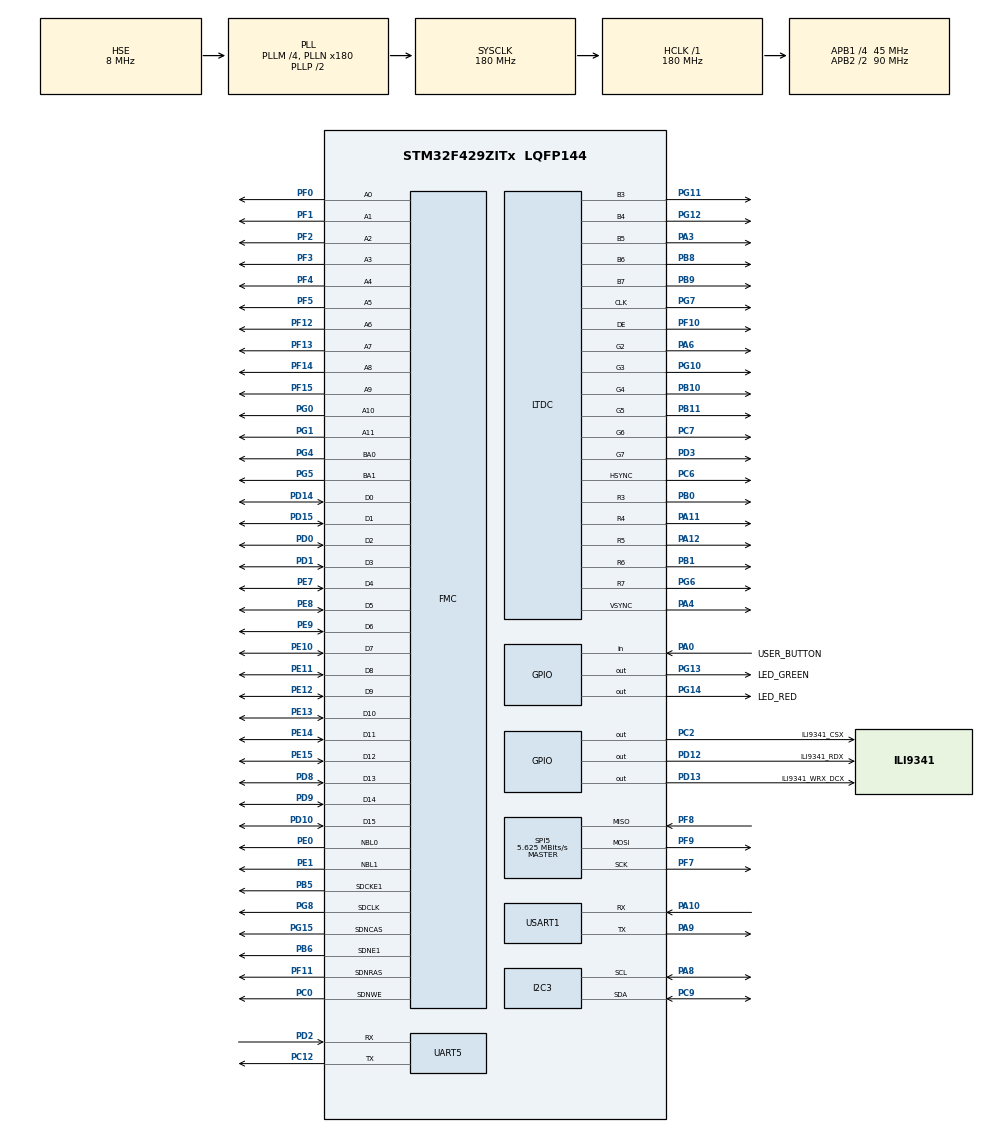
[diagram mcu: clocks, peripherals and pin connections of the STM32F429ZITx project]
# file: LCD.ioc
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DMA2D.ColorMode=DMA2D_OUTPUT_RGB565
FMC.CASLatency1=FMC_SDRAM_CAS_LATENCY_3
FMC.ExitSelfRefreshDelay1=7
FMC.LoadToActiveDelay1=2
FMC.RCDDelay1=2
FMC.RPDelay1=2
FMC.RPDelay2=2
FMC.RowCycleDelay1=7
FMC.RowCycleDelay2=7
FMC.SDClockPeriod1=FMC_SDRAM_CLOCK_PERIOD_2
FMC.SDClockPeriod2=FMC_SDRAM_CLOCK_PERIOD_2
FMC.SelfRefreshTime1=4
FMC.WriteRecoveryTime1=3
GRAPHICS.BSP.number=4
GRAPHICS.Check_OTM8009A_PixelFormat-STemWin_F429_439=1
GRAPHICS.DMA2D_Graphics-STemWin_F429_439=1
GRAPHICS.EA_1_Apptype=Window
GRAPHICS.EA_1_executable_name-STemWin_F429_439=GUIBuilder.exe
GRAPHICS.GUI_NUM_LAYERS-STemWin_F429_439=1
GRAPHICS.LIN_Frame_Buffer_Depth_Layer0-STemWin_F429_439=16
GRAPHICS.OPTIM_OS_use-STemWin_F429_439=4
GRAPHICS.USE_Embedded_Wizard-STemWin_F429_439=0
GRAPHICS.USE_STTouchGFX-STemWin_F429_439=0
GRAPHICS.UseGUIBuilder=Enabled
GRAPHICS.Use_SDRAM-STemWin_F429_439=SDRAM1_BANK2
GRAPHICS.Use_ili9341_Check-STemWin_F429_439=1
GRAPHICS0.BSP.STBoard=false
GRAPHICS0.BSP.api=Unknown
GRAPHICS0.BSP.i2caddr=0
GRAPHICS0.BSP.instance=PC2
GRAPHICS0.BSP.ip=GPIO
GRAPHICS0.BSP.mode=Output
GRAPHICS0.BSP.name=Chip Select
GRAPHICS0.BSP.solution=PC2
GRAPHICS1.BSP.STBoard=false
GRAPHICS1.BSP.api=Unknown
GRAPHICS1.BSP.i2caddr=0
GRAPHICS1.BSP.instance=PD13
GRAPHICS1.BSP.ip=GPIO
GRAPHICS1.BSP.mode=Output
GRAPHICS1.BSP.name=WRX High
GRAPHICS1.BSP.solution=PD13
GRAPHICS2.BSP.STBoard=false
GRAPHICS2.BSP.api=Unknown
GRAPHICS2.BSP.i2caddr=0
GRAPHICS2.BSP.instance=SPI5
GRAPHICS2.BSP.ip=SPI
GRAPHICS2.BSP.mode=Full-Duplex Master
GRAPHICS2.BSP.name=SPI_PIN
GRAPHICS2.BSP.solution=SPI5
GRAPHICS3.BSP.STBoard=false
GRAPHICS3.BSP.api=Unknown
GRAPHICS3.BSP.i2caddr=0
GRAPHICS3.BSP.instance=PD12
GRAPHICS3.BSP.ip=GPIO
GRAPHICS3.BSP.mode=Output
GRAPHICS3.BSP.name=RDX High
GRAPHICS3.BSP.solution=PD12
LTDC.ActiveH=320
LTDC.ActiveW=240
LTDC.Alpha_L0=255
LTDC.BlendingFactor1_L0=LTDC_BLENDING_FACTOR1_PAxCA
LTDC.BlendingFactor2_L0=LTDC_BLENDING_FACTOR2_PAxCA
LTDC.FBStartAdress_L0=0xd0200000
LTDC.HBP=20
LTDC.HFP=10
LTDC.HSync=10
LTDC.ImageHeight_L0=320
LTDC.ImageWidth_L0=240
LTDC.Layers=0
LTDC.PixelFormat_L0=LTDC_PIXEL_FORMAT_RGB565
LTDC.VFP=4
LTDC.VSync=2
LTDC.WindowX1_L0=240
LTDC.WindowY1_L0=320
Mcu.Family=STM32F4
Mcu.Name=STM32F429ZITx
Mcu.Package=LQFP144
NVIC.DMA2D_IRQn=true\:0\:0\:false\:false\:true\:true\:true
NVIC.LTDC_IRQn=true\:0\:0\:false\:false\:true\:true\:true
NVIC.PriorityGroup=NVIC_PRIORITYGROUP_4
NVIC.UART5_IRQn=true\:0\:0\:false\:false\:true\:true\:true
NVIC.USART1_IRQn=true\:0\:0\:false\:false\:true\:true\:true
PA0/WKUP.GPIO_Label=USER_BUTTON
PA0/WKUP.Signal=GPIO_Input
PA10.Mode=Asynchronous
PA10.Signal=USART1_RX
PA11.Mode=RGB565
PA11.Signal=LTDC_R4
PA12.Mode=RGB565
PA12.Signal=LTDC_R5
PA3.Mode=RGB565
PA3.Signal=LTDC_B5
PA4.Mode=RGB565
PA4.Signal=LTDC_VSYNC
PA6.Mode=RGB565
PA6.Signal=LTDC_G2
PA8.Mode=I2C
PA8.Signal=I2C3_SCL
PA9.Mode=Asynchronous
PA9.Signal=USART1_TX
PB0.Mode=RGB565
PB0.Signal=LTDC_R3
PB1.Mode=RGB565
PB1.Signal=LTDC_R6
PB10.Mode=RGB565
PB10.Signal=LTDC_G4
PB11.Mode=RGB565
PB11.Signal=LTDC_G5
PB5.Mode=SdramChipSelect2_1
PB5.Signal=FMC_SDCKE1
PB6.Mode=SdramChipSelect2_1
PB6.Signal=FMC_SDNE1
PB8.Mode=RGB565
PB8.Signal=LTDC_B6
PB9.Mode=RGB565
PB9.Signal=LTDC_B7
PC0.Signal=FMC_SDNWE
PC12.Mode=Asynchronous
PC12.Signal=UART5_TX
PC2.GPIO_Label=ILI9341_CSX
PC2.Signal=GPIO_Output
PC6.Mode=RGB565
PC6.Signal=LTDC_HSYNC
PC7.Mode=RGB565
PC7.Signal=LTDC_G6
PC9.Mode=I2C
PC9.Signal=I2C3_SDA
PD0.Signal=FMC_D2_DA2
PD1.Signal=FMC_D3_DA3
PD10.Signal=FMC_D15_DA15
PD12.GPIO_Label=ILI9341_RDX
PD12.Signal=GPIO_Output
PD13.GPIO_Label=ILI9341_WRX_DCX
PD13.Signal=GPIO_Output
PD14.Signal=FMC_D0_DA0
PD15.Signal=FMC_D1_DA1
PD2.Mode=Asynchronous
PD2.Signal=UART5_RX
PD3.Mode=RGB565
PD3.Signal=LTDC_G7
PD8.Signal=FMC_D13_DA13
PD9.Signal=FMC_D14_DA14
PE0.Signal=FMC_NBL0
PE1.Signal=FMC_NBL1
PE10.Signal=FMC_D7_DA7
PE11.Signal=FMC_D8_DA8
PE12.Signal=FMC_D9_DA9
PE13.Signal=FMC_D10_DA10
PE14.Signal=FMC_D11_DA11
PE15.Signal=FMC_D12_DA12
PE7.Signal=FMC_D4_DA4
PE8.Signal=FMC_D5_DA5
PE9.Signal=FMC_D6_DA6
PF0.Signal=FMC_A0
PF1.Signal=FMC_A1
PF10.Mode=RGB565
PF10.Signal=LTDC_DE
PF11.Signal=FMC_SDNRAS
PF12.Signal=FMC_A6
PF13.Signal=FMC_A7
PF14.Signal=FMC_A8
PF15.Signal=FMC_A9
PF2.Signal=FMC_A2
PF3.Signal=FMC_A3
PF4.Signal=FMC_A4
PF5.Signal=FMC_A5
PF7.Mode=Full_Duplex_Master
PF7.Signal=SPI5_SCK
PF8.Mode=Full_Duplex_Master
PF8.Signal=SPI5_MISO
PF9.Mode=Full_Duplex_Master
PF9.Signal=SPI5_MOSI
PG0.Signal=FMC_A10
PG1.Signal=FMC_A11
PG10.Mode=RGB565
PG10.Signal=LTDC_G3
PG11.Mode=RGB565
PG11.Signal=LTDC_B3
PG12.Mode=RGB565
PG12.Signal=LTDC_B4
PG13.GPIO_Label=LED_GREEN
PG13.Signal=GPIO_Output
PG14.GPIO_Label=LED_RED
PG14.Signal=GPIO_Output
PG15.Signal=FMC_SDNCAS
PG4.Signal=FMC_A14_BA0
PG5.Signal=FMC_A15_BA1
PG6.Mode=RGB565
PG6.Signal=LTDC_R7
PG7.Mode=RGB565
PG7.Signal=LTDC_CLK
PG8.Signal=FMC_SDCLK
PH0/OSC_IN.Mode=HSE-External-Oscillator
PH0/OSC_IN.Signal=RCC_OSC_IN
PH1/OSC_OUT.Mode=HSE-External-Oscillator
PH1/OSC_OUT.Signal=RCC_OSC_OUT
ProjectManager.HeapSize=0x1000
ProjectManager.StackSize=0x1000
ProjectManager.TargetToolchain=TrueSTUDIO
RCC.48MHZClocksFreq_Value=90000000
RCC.AHBFreq_Value=180000000
RCC.APB1CLKDivider=RCC_HCLK_DIV4
RCC.APB1Freq_Value=45000000
RCC.APB1TimFreq_Value=90000000
RCC.APB2CLKDivider=RCC_HCLK_DIV2
RCC.APB2Freq_Value=90000000
RCC.APB2TimFreq_Value=180000000
RCC.CortexFreq_Value=180000000
RCC.HCLKFreq_Value=180000000
RCC.HSE_VALUE=8000000
RCC.HSI_VALUE=16000000
RCC.LSE_VALUE=32768
RCC.PLLM=4
RCC.PLLN=180
RCC.PLLSAIN=50
RCC.PLLSAIR=5
RCC.PLLSourceVirtual=RCC_PLLSOURCE_HSE
RCC.SYSCLKFreq_VALUE=180000000
RCC.SYSCLKSource=RCC_SYSCLKSOURCE_PLLCLK
RCC.VCOOutputFreq_Value=360000000
SH.FMC_A0.0=FMC_A0,12b-sda1
SH.FMC_A1.0=FMC_A1,12b-sda1
SH.FMC_A10.0=FMC_A10,12b-sda1
SH.FMC_A11.0=FMC_A11,12b-sda1
SH.FMC_A14_BA0.0=FMC_BA0,FourSdramBanks1
SH.FMC_A15_BA1.0=FMC_BA1,FourSdramBanks1
SH.FMC_A2.0=FMC_A2,12b-sda1
SH.FMC_A3.0=FMC_A3,12b-sda1
SH.FMC_A4.0=FMC_A4,12b-sda1
SH.FMC_A5.0=FMC_A5,12b-sda1
SH.FMC_A6.0=FMC_A6,12b-sda1
SH.FMC_A7.0=FMC_A7,12b-sda1
SH.FMC_A8.0=FMC_A8,12b-sda1
SH.FMC_A9.0=FMC_A9,12b-sda1
SH.FMC_D0_DA0.0=FMC_D0,sd-16b-d1
SH.FMC_D10_DA10.0=FMC_D10,sd-16b-d1
SH.FMC_D11_DA11.0=FMC_D11,sd-16b-d1
SH.FMC_D12_DA12.0=FMC_D12,sd-16b-d1
SH.FMC_D13_DA13.0=FMC_D13,sd-16b-d1
SH.FMC_D14_DA14.0=FMC_D14,sd-16b-d1
SH.FMC_D15_DA15.0=FMC_D15,sd-16b-d1
SH.FMC_D1_DA1.0=FMC_D1,sd-16b-d1
SH.FMC_D2_DA2.0=FMC_D2,sd-16b-d1
SH.FMC_D3_DA3.0=FMC_D3,sd-16b-d1
SH.FMC_D4_DA4.0=FMC_D4,sd-16b-d1
SH.FMC_D5_DA5.0=FMC_D5,sd-16b-d1
SH.FMC_D6_DA6.0=FMC_D6,sd-16b-d1
SH.FMC_D7_DA7.0=FMC_D7,sd-16b-d1
SH.FMC_D8_DA8.0=FMC_D8,sd-16b-d1
SH.FMC_D9_DA9.0=FMC_D9,sd-16b-d1
SH.FMC_NBL0.0=FMC_NBL0,Sd2ByteEnable1
SH.FMC_NBL1.0=FMC_NBL1,Sd2ByteEnable1
SH.FMC_SDCLK.0=FMC_SDCLK,12b-sda1
SH.FMC_SDNCAS.0=FMC_SDNCAS,12b-sda1
SH.FMC_SDNRAS.0=FMC_SDNRAS,12b-sda1
SH.FMC_SDNWE.0=FMC_SDNWE,12b-sda1
SPI5.BaudRatePrescaler=SPI_BAUDRATEPRESCALER_16
SPI5.CalculateBaudRate=5.625 MBits/s
SPI5.Direction=SPI_DIRECTION_2LINES
SPI5.Mode=SPI_MODE_MASTER
SPI5.VirtualType=VM_MASTER
UART5.VirtualMode=Asynchronous
USART1.VirtualMode=VM_ASYNC
VP_CRC_VS_CRC.Mode=CRC_Activate
VP_DMA2D_VS_DMA2D.Mode=DMA2D_Activate
VP_GRAPHICS_VS-DisplayInterface-LTDC.Mode=Display Parallel Interface using LTDC
VP_GRAPHICS_VS-STemWin.Mode=STemWin_F429_439
board=custom

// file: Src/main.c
/* USER CODE BEGIN Header */
/**
  ******************************************************************************
  * @file           : main.c
  * @brief          : Main program body
  ******************************************************************************
  * @attention
  *
  * <h2><center>&copy; Copyright (c) 2019 STMicroelectronics.
  * All rights reserved.</center></h2>
  *
  * This software component is licensed by ST under Ultimate Liberty license
  * SLA0044, the "License"; You may not use this file except in compliance with
  * the License. You may obtain a copy of the License at:
  *                             www.st.com/SLA0044
  *
  ******************************************************************************
  */
/* USER CODE END Header */

#include "main.h"

/* USER CODE BEGIN Includes */
#include "stm32f429i_discovery_ts.h"
/* USER CODE END Includes */

CRC_HandleTypeDef hcrc;

I2C_HandleTypeDef hi2c3;

SPI_HandleTypeDef hspi5;

UART_HandleTypeDef huart5;
UART_HandleTypeDef huart1;

void SystemClock_Config(void);
static void MX_GPIO_Init(void);
static void MX_USART1_UART_Init(void);
static void MX_UART5_Init(void);
static void MX_GFXSIMULATOR_Init(void);
static void MX_CRC_Init(void);
static void MX_I2C3_Init(void);
extern void GRAPHICS_HW_Init(void);
extern void GRAPHICS_Init(void);
extern void GRAPHICS_MainTask(void);
void MX_SPI5_Init(void);

int main(void)
{

  /* MCU Configuration--------------------------------------------------------*/

  /* Reset of all peripherals, Initializes the Flash interface and the Systick. */
  HAL_Init();

  /* Configure the system clock */
  SystemClock_Config();

  /* Initialize all configured peripherals */
  MX_GPIO_Init();
 MX_SPI5_Init();
  MX_USART1_UART_Init();
  MX_UART5_Init();
  //MX_GFXSIMULATOR_Init();
  MX_CRC_Init();
  MX_I2C3_Init();

/* Initialise the graphical hardware */
  GRAPHICS_HW_Init();
	BSP_TS_Init(ILI9341_LCD_PIXEL_WIDTH, ILI9341_LCD_PIXEL_HEIGHT);

  /* Initialise the graphical stack engine */
  GRAPHICS_Init();

  /* Graphic application */
  GRAPHICS_MainTask();

  /* Infinite loop */
  for(;;);
}

void SystemClock_Config(void)
{
  RCC_OscInitTypeDef RCC_OscInitStruct = {0};
  RCC_ClkInitTypeDef RCC_ClkInitStruct = {0};
  RCC_PeriphCLKInitTypeDef PeriphClkInitStruct = {0};

  /** Configure the main internal regulator output voltage
  */
  __HAL_RCC_PWR_CLK_ENABLE();
  __HAL_PWR_VOLTAGESCALING_CONFIG(PWR_REGULATOR_VOLTAGE_SCALE1);
  /** Initializes the CPU, AHB and APB busses clocks
  */
  RCC_OscInitStruct.OscillatorType = RCC_OSCILLATORTYPE_HSE;
  RCC_OscInitStruct.HSEState = RCC_HSE_ON;
  RCC_OscInitStruct.PLL.PLLState = RCC_PLL_ON;
  RCC_OscInitStruct.PLL.PLLSource = RCC_PLLSOURCE_HSE;
  RCC_OscInitStruct.PLL.PLLM = 4;
  RCC_OscInitStruct.PLL.PLLN = 180;
  RCC_OscInitStruct.PLL.PLLP = RCC_PLLP_DIV2;
  RCC_OscInitStruct.PLL.PLLQ = 4;
  if (HAL_RCC_OscConfig(&RCC_OscInitStruct) != HAL_OK)
  {
    Error_Handler();
  }
  /** Activate the Over-Drive mode
  */
  if (HAL_PWREx_EnableOverDrive() != HAL_OK)
  {
    Error_Handler();
  }
  /** Initializes the CPU, AHB and APB busses clocks
  */
  RCC_ClkInitStruct.ClockType = RCC_CLOCKTYPE_HCLK|RCC_CLOCKTYPE_SYSCLK
                              |RCC_CLOCKTYPE_PCLK1|RCC_CLOCKTYPE_PCLK2;
  RCC_ClkInitStruct.SYSCLKSource = RCC_SYSCLKSOURCE_PLLCLK;
  RCC_ClkInitStruct.AHBCLKDivider = RCC_SYSCLK_DIV1;
  RCC_ClkInitStruct.APB1CLKDivider = RCC_HCLK_DIV4;
  RCC_ClkInitStruct.APB2CLKDivider = RCC_HCLK_DIV2;

  if (HAL_RCC_ClockConfig(&RCC_ClkInitStruct, FLASH_LATENCY_5) != HAL_OK)
  {
    Error_Handler();
  }
  PeriphClkInitStruct.PeriphClockSelection = RCC_PERIPHCLK_LTDC;
  PeriphClkInitStruct.PLLSAI.PLLSAIN = 50;
  PeriphClkInitStruct.PLLSAI.PLLSAIR = 5;
  PeriphClkInitStruct.PLLSAIDivR = RCC_PLLSAIDIVR_2;
  if (HAL_RCCEx_PeriphCLKConfig(&PeriphClkInitStruct) != HAL_OK)
  {
    Error_Handler();
  }
}

static void MX_CRC_Init(void)
{

  hcrc.Instance = CRC;
  if (HAL_CRC_Init(&hcrc) != HAL_OK)
  {
    Error_Handler();
  }

}

static void MX_GFXSIMULATOR_Init(void)
{

}

static void MX_I2C3_Init(void)
{

  hi2c3.Instance = I2C3;
  hi2c3.Init.ClockSpeed = 100000;
  hi2c3.Init.DutyCycle = I2C_DUTYCYCLE_2;
  hi2c3.Init.OwnAddress1 = 0;
  hi2c3.Init.AddressingMode = I2C_ADDRESSINGMODE_7BIT;
  hi2c3.Init.DualAddressMode = I2C_DUALADDRESS_DISABLE;
  hi2c3.Init.OwnAddress2 = 0;
  hi2c3.Init.GeneralCallMode = I2C_GENERALCALL_DISABLE;
  hi2c3.Init.NoStretchMode = I2C_NOSTRETCH_DISABLE;
  if (HAL_I2C_Init(&hi2c3) != HAL_OK)
  {
    Error_Handler();
  }
  /** Configure Analogue filter
  */
  if (HAL_I2CEx_ConfigAnalogFilter(&hi2c3, I2C_ANALOGFILTER_ENABLE) != HAL_OK)
  {
    Error_Handler();
  }
  /** Configure Digital filter
  */
  if (HAL_I2CEx_ConfigDigitalFilter(&hi2c3, 0) != HAL_OK)
  {
    Error_Handler();
  }

}

void MX_SPI5_Init(void)
{

  /* SPI5 parameter configuration*/
  hspi5.Instance = SPI5;
  hspi5.Init.Mode = SPI_MODE_MASTER;
  hspi5.Init.Direction = SPI_DIRECTION_2LINES;
  hspi5.Init.DataSize = SPI_DATASIZE_8BIT;
  hspi5.Init.CLKPolarity = SPI_POLARITY_LOW;
  hspi5.Init.CLKPhase = SPI_PHASE_1EDGE;
  hspi5.Init.NSS = SPI_NSS_SOFT;
  hspi5.Init.BaudRatePrescaler = SPI_BAUDRATEPRESCALER_16;
  hspi5.Init.FirstBit = SPI_FIRSTBIT_MSB;
  hspi5.Init.TIMode = SPI_TIMODE_DISABLE;
  hspi5.Init.CRCCalculation = SPI_CRCCALCULATION_DISABLE;
  hspi5.Init.CRCPolynomial = 10;
  if (HAL_SPI_Init(&hspi5) != HAL_OK)
  {
    Error_Handler();
  }

}

static void MX_UART5_Init(void)
{

  huart5.Instance = UART5;
  huart5.Init.BaudRate = 115200;
  huart5.Init.WordLength = UART_WORDLENGTH_8B;
  huart5.Init.StopBits = UART_STOPBITS_1;
  huart5.Init.Parity = UART_PARITY_NONE;
  huart5.Init.Mode = UART_MODE_TX_RX;
  huart5.Init.HwFlowCtl = UART_HWCONTROL_NONE;
  huart5.Init.OverSampling = UART_OVERSAMPLING_16;
  if (HAL_UART_Init(&huart5) != HAL_OK)
  {
    Error_Handler();
  }

}

static void MX_USART1_UART_Init(void)
{

  huart1.Instance = USART1;
  huart1.Init.BaudRate = 115200;
  huart1.Init.WordLength = UART_WORDLENGTH_8B;
  huart1.Init.StopBits = UART_STOPBITS_1;
  huart1.Init.Parity = UART_PARITY_NONE;
  huart1.Init.Mode = UART_MODE_TX_RX;
  huart1.Init.HwFlowCtl = UART_HWCONTROL_NONE;
  huart1.Init.OverSampling = UART_OVERSAMPLING_16;
  if (HAL_UART_Init(&huart1) != HAL_OK)
  {
    Error_Handler();
  }

}

static void MX_GPIO_Init(void)
{
  GPIO_InitTypeDef GPIO_InitStruct = {0};

  /* GPIO Ports Clock Enable */
  __HAL_RCC_GPIOF_CLK_ENABLE();
  __HAL_RCC_GPIOH_CLK_ENABLE();
  __HAL_RCC_GPIOC_CLK_ENABLE();
  __HAL_RCC_GPIOA_CLK_ENABLE();
  __HAL_RCC_GPIOB_CLK_ENABLE();
  __HAL_RCC_GPIOG_CLK_ENABLE();
  __HAL_RCC_GPIOE_CLK_ENABLE();
  __HAL_RCC_GPIOD_CLK_ENABLE();

  /*Configure GPIO pin Output Level */
  HAL_GPIO_WritePin(ILI9341_CSX_GPIO_Port, ILI9341_CSX_Pin, GPIO_PIN_RESET);

  /*Configure GPIO pin Output Level */
  HAL_GPIO_WritePin(GPIOD, ILI9341_RDX_Pin|ILI9341_WRX_DCX_Pin, GPIO_PIN_RESET);

  /*Configure GPIO pin Output Level */
  HAL_GPIO_WritePin(GPIOG, LED_GREEN_Pin|LED_RED_Pin, GPIO_PIN_RESET);

  /*Configure GPIO pin : ILI9341_CSX_Pin */
  GPIO_InitStruct.Pin = ILI9341_CSX_Pin;
  GPIO_InitStruct.Mode = GPIO_MODE_OUTPUT_PP;
  GPIO_InitStruct.Pull = GPIO_NOPULL;
  GPIO_InitStruct.Speed = GPIO_SPEED_FREQ_LOW;
  HAL_GPIO_Init(ILI9341_CSX_GPIO_Port, &GPIO_InitStruct);

  /*Configure GPIO pin : USER_BUTTON_Pin */
  GPIO_InitStruct.Pin = USER_BUTTON_Pin;
  GPIO_InitStruct.Mode = GPIO_MODE_INPUT;
  GPIO_InitStruct.Pull = GPIO_NOPULL;
  HAL_GPIO_Init(USER_BUTTON_GPIO_Port, &GPIO_InitStruct);

  /*Configure GPIO pins : ILI9341_RDX_Pin ILI9341_WRX_DCX_Pin */
  GPIO_InitStruct.Pin = ILI9341_RDX_Pin|ILI9341_WRX_DCX_Pin;
  GPIO_InitStruct.Mode = GPIO_MODE_OUTPUT_PP;
  GPIO_InitStruct.Pull = GPIO_NOPULL;
  GPIO_InitStruct.Speed = GPIO_SPEED_FREQ_LOW;
  HAL_GPIO_Init(GPIOD, &GPIO_InitStruct);

  /*Configure GPIO pins : LED_GREEN_Pin LED_RED_Pin */
  GPIO_InitStruct.Pin = LED_GREEN_Pin|LED_RED_Pin;
  GPIO_InitStruct.Mode = GPIO_MODE_OUTPUT_PP;
  GPIO_InitStruct.Pull = GPIO_NOPULL;
  GPIO_InitStruct.Speed = GPIO_SPEED_FREQ_LOW;
  HAL_GPIO_Init(GPIOG, &GPIO_InitStruct);

}

void Error_Handler(void)
{
}

/************************ (C) COPYRIGHT STMicroelectronics *****END OF FILE****/
